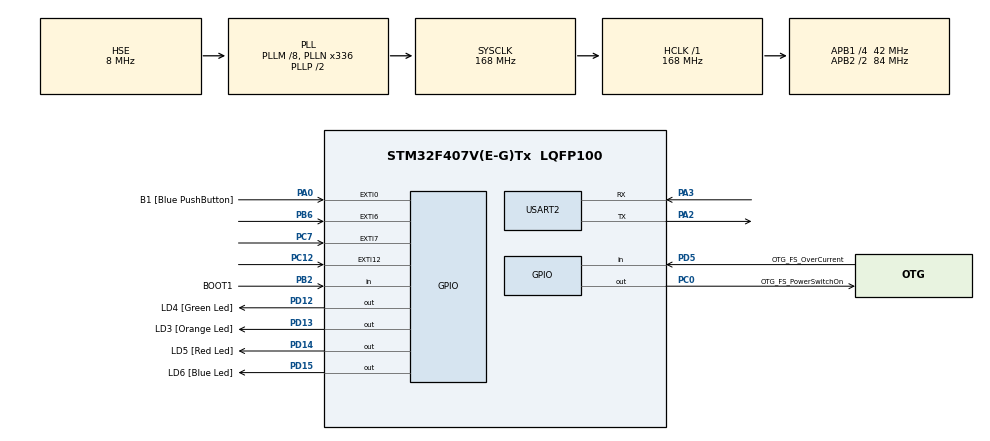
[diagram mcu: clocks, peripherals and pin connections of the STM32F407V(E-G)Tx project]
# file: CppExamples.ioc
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Mcu.Family=STM32F4
Mcu.Name=STM32F407V(E-G)Tx
Mcu.Package=LQFP100
NVIC.PriorityGroup=NVIC_PRIORITYGROUP_0
PA0-WKUP.GPIO_Label=B1 [Blue PushButton]
PA0-WKUP.GPIO_ModeDefaultEXTI=GPIO_MODE_EVT_RISING
PA0-WKUP.GPIO_PuPd=GPIO_NOPULL
PA0-WKUP.Signal=GPXTI0
PA13.GPIO_Label=SWDIO
PA13.Mode=Trace_Asynchronous_SW
PA13.Signal=SYS_JTMS-SWDIO
PA14.GPIO_Label=SWCLK
PA14.Mode=Trace_Asynchronous_SW
PA14.Signal=SYS_JTCK-SWCLK
PA2.Mode=Asynchronous
PA2.Signal=USART2_TX
PA3.Mode=Asynchronous
PA3.Signal=USART2_RX
PB2.GPIO_Label=BOOT1
PB2.GPIO_Mode=GPIO_MODE_INPUT
PB2.GPIO_PuPd=GPIO_NOPULL
PB2.Signal=GPIO_Input
PB3.Mode=Trace_Asynchronous_SW
PB3.Signal=SYS_JTDO-SWO
PB6.Signal=GPXTI6
PC0.GPIO_Label=OTG_FS_PowerSwitchOn
PC0.GPIO_PuPd=GPIO_NOPULL
PC0.GPIO_Speed=GPIO_SPEED_FREQ_LOW
PC0.PinState=GPIO_PIN_SET
PC0.Signal=GPIO_Output
PC12.Signal=GPXTI12
PC14-OSC32_IN.GPIO_Label=PC14-OSC32_IN
PC14-OSC32_IN.Mode=LSE-External-Oscillator
PC14-OSC32_IN.Signal=RCC_OSC32_IN
PC15-OSC32_OUT.GPIO_Label=PC15-OSC32_OUT
PC15-OSC32_OUT.Mode=LSE-External-Oscillator
PC15-OSC32_OUT.Signal=RCC_OSC32_OUT
PC7.Signal=GPXTI7
PD12.GPIO_Label=LD4 [Green Led]
PD12.GPIO_PuPd=GPIO_NOPULL
PD12.GPIO_Speed=GPIO_SPEED_FREQ_LOW
PD12.Signal=GPIO_Output
PD13.GPIO_Label=LD3 [Orange Led]
PD13.GPIO_PuPd=GPIO_NOPULL
PD13.GPIO_Speed=GPIO_SPEED_FREQ_LOW
PD13.Signal=GPIO_Output
PD14.GPIO_Label=LD5 [Red Led]
PD14.GPIO_PuPd=GPIO_NOPULL
PD14.GPIO_Speed=GPIO_SPEED_FREQ_LOW
PD14.Signal=GPIO_Output
PD15.GPIO_Label=LD6 [Blue Led]
PD15.GPIO_PuPd=GPIO_NOPULL
PD15.GPIO_Speed=GPIO_SPEED_FREQ_LOW
PD15.Signal=GPIO_Output
PD5.GPIO_Label=OTG_FS_OverCurrent
PD5.GPIO_Mode=GPIO_MODE_INPUT
PD5.GPIO_PuPd=GPIO_NOPULL
PD5.Signal=GPIO_Input
PH0-OSC_IN.GPIO_Label=PH0-OSC_IN
PH0-OSC_IN.Mode=HSE-External-Oscillator
PH0-OSC_IN.Signal=RCC_OSC_IN
PH1-OSC_OUT.GPIO_Label=PH1-OSC_OUT
PH1-OSC_OUT.Mode=HSE-External-Oscillator
PH1-OSC_OUT.Signal=RCC_OSC_OUT
ProjectManager.HeapSize=0x200
ProjectManager.StackSize=0x400
ProjectManager.TargetToolchain=STM32CubeIDE
RCC.48MHZClocksFreq_Value=48000000
RCC.AHBFreq_Value=168000000
RCC.APB1CLKDivider=RCC_HCLK_DIV4
RCC.APB1Freq_Value=42000000
RCC.APB1TimFreq_Value=84000000
RCC.APB2CLKDivider=RCC_HCLK_DIV2
RCC.APB2Freq_Value=84000000
RCC.APB2TimFreq_Value=168000000
RCC.CortexFreq_Value=168000000
RCC.HCLKFreq_Value=168000000
RCC.HSE_VALUE=8000000
RCC.HSI_VALUE=16000000
RCC.PLLM=8
RCC.PLLN=336
RCC.PLLQ=7
RCC.PLLSourceVirtual=RCC_PLLSOURCE_HSE
RCC.SYSCLKFreq_VALUE=168000000
RCC.SYSCLKSource=RCC_SYSCLKSOURCE_PLLCLK
RCC.VCOOutputFreq_Value=336000000
USART2.VirtualMode=VM_ASYNC
board=STM32F407G-DISC1

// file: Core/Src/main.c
/* USER CODE BEGIN Header */
/**
  ******************************************************************************
  * @file           : main.c
  * @brief          : Main program body
  ******************************************************************************
  * @attention
  *
  * Copyright (c) 2022 STMicroelectronics.
  * All rights reserved.
  *
  * This software is licensed under terms that can be found in the LICENSE file
  * in the root directory of this software component.
  * If no LICENSE file comes with this software, it is provided AS-IS.
  *
  ******************************************************************************
  */
/* USER CODE END Header */
#include "main.h"

/* USER CODE BEGIN Includes */
#include "stdio.h"
#include "retarget.h"
/* USER CODE END Includes */

UART_HandleTypeDef huart2;

void SystemClock_Config(void);
static void MX_GPIO_Init(void);
static void MX_USART2_UART_Init(void);

int main(void)
{

  /* MCU Configuration--------------------------------------------------------*/

  /* Reset of all peripherals, Initializes the Flash interface and the Systick. */
  HAL_Init();

  /* Configure the system clock */
  SystemClock_Config();

  /* Initialize all configured peripherals */
  MX_GPIO_Init();
  MX_USART2_UART_Init();
  /* USER CODE BEGIN 2 */
  RetargetInit(&huart2);
  /* USER CODE END 2 */

  /* Infinite loop */
  while (1)
  {

    /* USER CODE BEGIN 3 */

	  CppMain();

  }
  /* USER CODE END 3 */
}

void SystemClock_Config(void)
{
  RCC_OscInitTypeDef RCC_OscInitStruct = {0};
  RCC_ClkInitTypeDef RCC_ClkInitStruct = {0};

  /** Configure the main internal regulator output voltage
  */
  __HAL_RCC_PWR_CLK_ENABLE();
  __HAL_PWR_VOLTAGESCALING_CONFIG(PWR_REGULATOR_VOLTAGE_SCALE1);

  /** Initializes the RCC Oscillators according to the specified parameters
  * in the RCC_OscInitTypeDef structure.
  */
  RCC_OscInitStruct.OscillatorType = RCC_OSCILLATORTYPE_HSE;
  RCC_OscInitStruct.HSEState = RCC_HSE_ON;
  RCC_OscInitStruct.PLL.PLLState = RCC_PLL_ON;
  RCC_OscInitStruct.PLL.PLLSource = RCC_PLLSOURCE_HSE;
  RCC_OscInitStruct.PLL.PLLM = 8;
  RCC_OscInitStruct.PLL.PLLN = 336;
  RCC_OscInitStruct.PLL.PLLP = RCC_PLLP_DIV2;
  RCC_OscInitStruct.PLL.PLLQ = 7;
  if (HAL_RCC_OscConfig(&RCC_OscInitStruct) != HAL_OK)
  {
    Error_Handler();
  }

  /** Initializes the CPU, AHB and APB buses clocks
  */
  RCC_ClkInitStruct.ClockType = RCC_CLOCKTYPE_HCLK|RCC_CLOCKTYPE_SYSCLK
                              |RCC_CLOCKTYPE_PCLK1|RCC_CLOCKTYPE_PCLK2;
  RCC_ClkInitStruct.SYSCLKSource = RCC_SYSCLKSOURCE_PLLCLK;
  RCC_ClkInitStruct.AHBCLKDivider = RCC_SYSCLK_DIV1;
  RCC_ClkInitStruct.APB1CLKDivider = RCC_HCLK_DIV4;
  RCC_ClkInitStruct.APB2CLKDivider = RCC_HCLK_DIV2;

  if (HAL_RCC_ClockConfig(&RCC_ClkInitStruct, FLASH_LATENCY_5) != HAL_OK)
  {
    Error_Handler();
  }
}

static void MX_USART2_UART_Init(void)
{

  huart2.Instance = USART2;
  huart2.Init.BaudRate = 115200;
  huart2.Init.WordLength = UART_WORDLENGTH_8B;
  huart2.Init.StopBits = UART_STOPBITS_1;
  huart2.Init.Parity = UART_PARITY_NONE;
  huart2.Init.Mode = UART_MODE_TX_RX;
  huart2.Init.HwFlowCtl = UART_HWCONTROL_NONE;
  huart2.Init.OverSampling = UART_OVERSAMPLING_16;
  if (HAL_UART_Init(&huart2) != HAL_OK)
  {
    Error_Handler();
  }

}

static void MX_GPIO_Init(void)
{
  GPIO_InitTypeDef GPIO_InitStruct = {0};

  /* GPIO Ports Clock Enable */
  __HAL_RCC_GPIOC_CLK_ENABLE();
  __HAL_RCC_GPIOH_CLK_ENABLE();
  __HAL_RCC_GPIOA_CLK_ENABLE();
  __HAL_RCC_GPIOB_CLK_ENABLE();
  __HAL_RCC_GPIOD_CLK_ENABLE();

  /*Configure GPIO pin Output Level */
  HAL_GPIO_WritePin(OTG_FS_PowerSwitchOn_GPIO_Port, OTG_FS_PowerSwitchOn_Pin, GPIO_PIN_SET);

  /*Configure GPIO pin Output Level */
  HAL_GPIO_WritePin(GPIOD, LD4_Pin|LD3_Pin|LD5_Pin|LD6_Pin, GPIO_PIN_RESET);

  /*Configure GPIO pin : OTG_FS_PowerSwitchOn_Pin */
  GPIO_InitStruct.Pin = OTG_FS_PowerSwitchOn_Pin;
  GPIO_InitStruct.Mode = GPIO_MODE_OUTPUT_PP;
  GPIO_InitStruct.Pull = GPIO_NOPULL;
  GPIO_InitStruct.Speed = GPIO_SPEED_FREQ_LOW;
  HAL_GPIO_Init(OTG_FS_PowerSwitchOn_GPIO_Port, &GPIO_InitStruct);

  /*Configure GPIO pin : B1_Pin */
  GPIO_InitStruct.Pin = B1_Pin;
  GPIO_InitStruct.Mode = GPIO_MODE_EVT_RISING;
  GPIO_InitStruct.Pull = GPIO_NOPULL;
  HAL_GPIO_Init(B1_GPIO_Port, &GPIO_InitStruct);

  /*Configure GPIO pin : BOOT1_Pin */
  GPIO_InitStruct.Pin = BOOT1_Pin;
  GPIO_InitStruct.Mode = GPIO_MODE_INPUT;
  GPIO_InitStruct.Pull = GPIO_NOPULL;
  HAL_GPIO_Init(BOOT1_GPIO_Port, &GPIO_InitStruct);

  /*Configure GPIO pins : LD4_Pin LD3_Pin LD5_Pin LD6_Pin */
  GPIO_InitStruct.Pin = LD4_Pin|LD3_Pin|LD5_Pin|LD6_Pin;
  GPIO_InitStruct.Mode = GPIO_MODE_OUTPUT_PP;
  GPIO_InitStruct.Pull = GPIO_NOPULL;
  GPIO_InitStruct.Speed = GPIO_SPEED_FREQ_LOW;
  HAL_GPIO_Init(GPIOD, &GPIO_InitStruct);

  /*Configure GPIO pins : PC7 PC12 */
  GPIO_InitStruct.Pin = GPIO_PIN_7|GPIO_PIN_12;
  GPIO_InitStruct.Mode = GPIO_MODE_IT_RISING;
  GPIO_InitStruct.Pull = GPIO_NOPULL;
  HAL_GPIO_Init(GPIOC, &GPIO_InitStruct);

  /*Configure GPIO pin : OTG_FS_OverCurrent_Pin */
  GPIO_InitStruct.Pin = OTG_FS_OverCurrent_Pin;
  GPIO_InitStruct.Mode = GPIO_MODE_INPUT;
  GPIO_InitStruct.Pull = GPIO_NOPULL;
  HAL_GPIO_Init(OTG_FS_OverCurrent_GPIO_Port, &GPIO_InitStruct);

  /*Configure GPIO pin : PB6 */
  GPIO_InitStruct.Pin = GPIO_PIN_6;
  GPIO_InitStruct.Mode = GPIO_MODE_IT_RISING;
  GPIO_InitStruct.Pull = GPIO_NOPULL;
  HAL_GPIO_Init(GPIOB, &GPIO_InitStruct);

}

void Error_Handler(void)
{
  __disable_irq();
  while (1)
  {
  }
}
